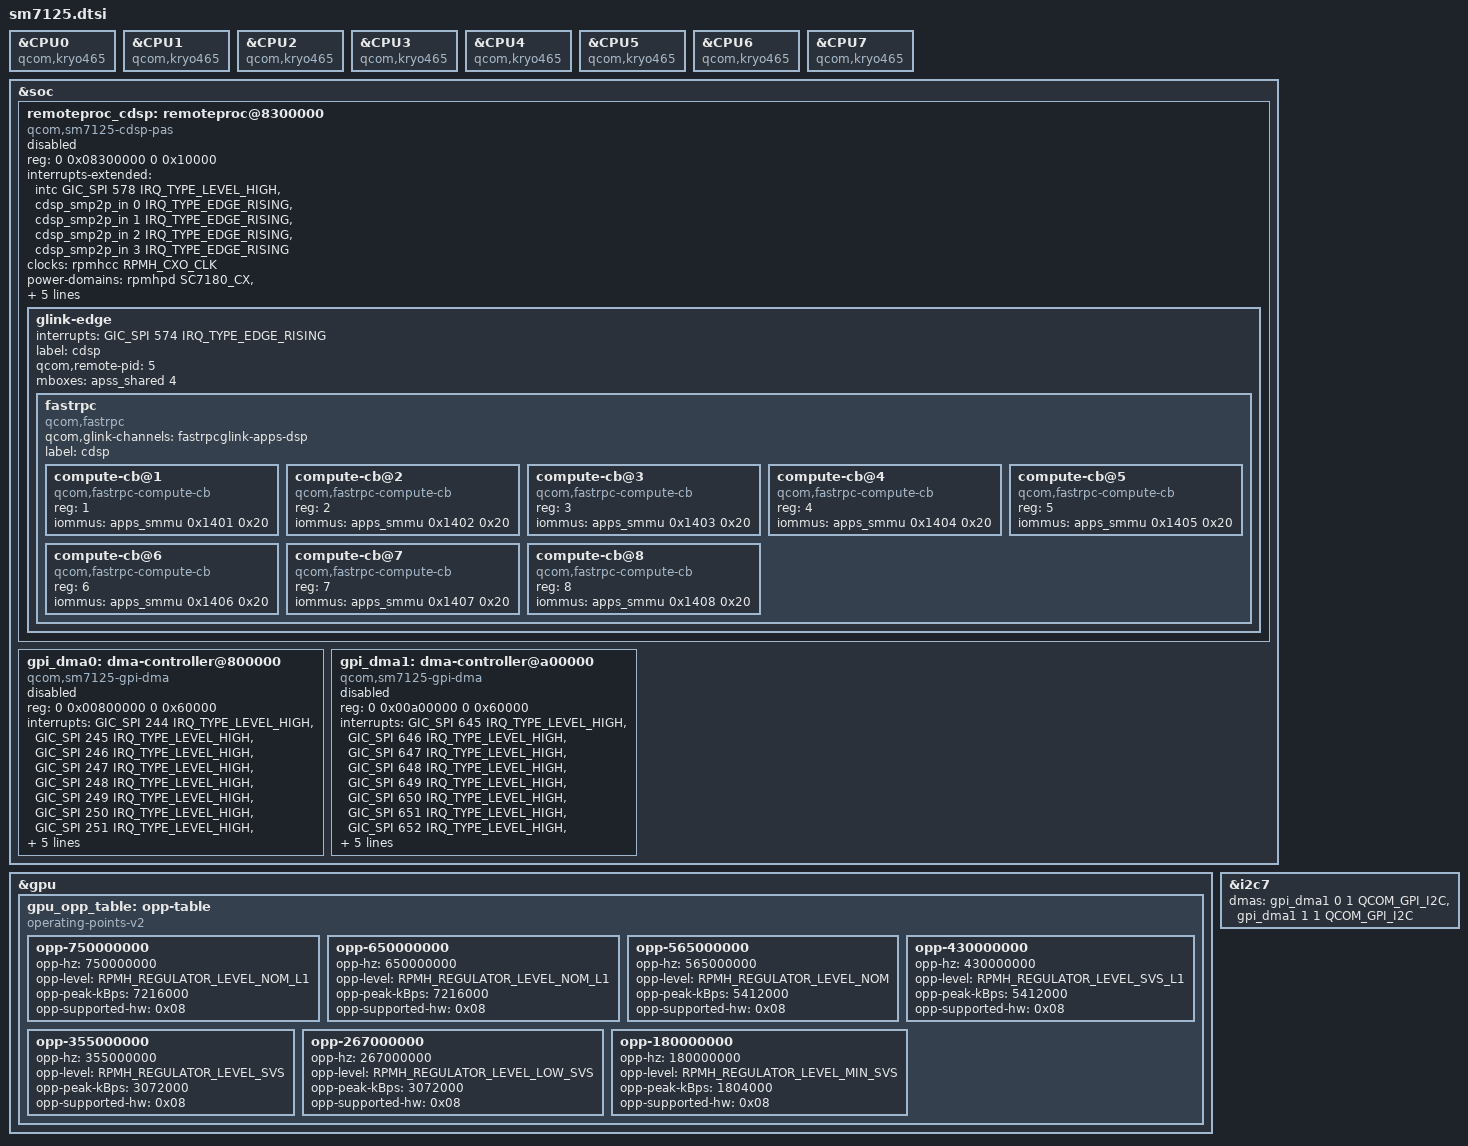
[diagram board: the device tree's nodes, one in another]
// SPDX-License-Identifier: GPL-2.0
/*
 * Copyright (c) 2021, The Linux Foundation. All rights reserved.
 */

#include <dt-bindings/dma/qcom-gpi.h>
#include "sc7180.dtsi"

/* SM7125 uses Kryo 465 instead of Kryo 468 */
&CPU0 { compatible = "qcom,kryo465"; };
&CPU1 { compatible = "qcom,kryo465"; };
&CPU2 { compatible = "qcom,kryo465"; };
&CPU3 { compatible = "qcom,kryo465"; };
&CPU4 { compatible = "qcom,kryo465"; };
&CPU5 { compatible = "qcom,kryo465"; };
&CPU6 { compatible = "qcom,kryo465"; };
&CPU7 { compatible = "qcom,kryo465"; };

&soc {
	remoteproc_cdsp: remoteproc@8300000 {
		compatible = "qcom,sm7125-cdsp-pas", "qcom,sm6350-cdsp-pas";
		reg = <0 0x08300000 0 0x10000>;

		interrupts-extended = <&intc GIC_SPI 578 IRQ_TYPE_LEVEL_HIGH>,
						<&cdsp_smp2p_in 0 IRQ_TYPE_EDGE_RISING>,
						<&cdsp_smp2p_in 1 IRQ_TYPE_EDGE_RISING>,
						<&cdsp_smp2p_in 2 IRQ_TYPE_EDGE_RISING>,
						<&cdsp_smp2p_in 3 IRQ_TYPE_EDGE_RISING>;
		interrupt-names = "wdog", "fatal", "ready",
					"handover", "stop-ack";

		clocks = <&rpmhcc RPMH_CXO_CLK>;
		clock-names = "xo";

		power-domains = <&rpmhpd SC7180_CX>,
				<&rpmhpd SC7180_MX>;
		power-domain-names = "cx", "mx";

		memory-region = <&cdsp_mem>;

		qcom,qmp = <&aoss_qmp>;

		qcom,smem-states = <&cdsp_smp2p_out 0>;
		qcom,smem-state-names = "stop";

		status = "disabled";

		glink-edge {
			interrupts = <GIC_SPI 574 IRQ_TYPE_EDGE_RISING>;
			label = "cdsp";
			qcom,remote-pid = <5>;
			mboxes = <&apss_shared 4>;

			fastrpc {
				compatible = "qcom,fastrpc";
				qcom,glink-channels = "fastrpcglink-apps-dsp";
				label = "cdsp";
				#address-cells = <1>;
				#size-cells = <0>;

				compute-cb@1 {
					compatible = "qcom,fastrpc-compute-cb";
					reg = <1>;
					iommus = <&apps_smmu 0x1401 0x20>;
				};

				compute-cb@2 {
					compatible = "qcom,fastrpc-compute-cb";
					reg = <2>;
					iommus = <&apps_smmu 0x1402 0x20>;
				};

				compute-cb@3 {
					compatible = "qcom,fastrpc-compute-cb";
					reg = <3>;
					iommus = <&apps_smmu 0x1403 0x20>;
				};

				compute-cb@4 {
					compatible = "qcom,fastrpc-compute-cb";
					reg = <4>;
					iommus = <&apps_smmu 0x1404 0x20>;
				};

				compute-cb@5 {
					compatible = "qcom,fastrpc-compute-cb";
					reg = <5>;
					iommus = <&apps_smmu 0x1405 0x20>;
				};

				compute-cb@6 {
					compatible = "qcom,fastrpc-compute-cb";
					reg = <6>;
					iommus = <&apps_smmu 0x1406 0x20>;
				};

				compute-cb@7 {
					compatible = "qcom,fastrpc-compute-cb";
					reg = <7>;
					iommus = <&apps_smmu 0x1407 0x20>;
				};

				compute-cb@8 {
					compatible = "qcom,fastrpc-compute-cb";
					reg = <8>;
					iommus = <&apps_smmu 0x1408 0x20>;
				};

				/* note: secure cb9 in downstream */
			};
		};
	};

	gpi_dma0: dma-controller@800000  {
		compatible = "qcom,sm7125-gpi-dma", "qcom,sm6350-gpi-dma";
		reg = <0 0x00800000 0 0x60000>;
		interrupts = <GIC_SPI 244 IRQ_TYPE_LEVEL_HIGH>,
					<GIC_SPI 245 IRQ_TYPE_LEVEL_HIGH>,
					<GIC_SPI 246 IRQ_TYPE_LEVEL_HIGH>,
					<GIC_SPI 247 IRQ_TYPE_LEVEL_HIGH>,
					<GIC_SPI 248 IRQ_TYPE_LEVEL_HIGH>,
					<GIC_SPI 249 IRQ_TYPE_LEVEL_HIGH>,
					<GIC_SPI 250 IRQ_TYPE_LEVEL_HIGH>,
					<GIC_SPI 251 IRQ_TYPE_LEVEL_HIGH>,
					<GIC_SPI 252 IRQ_TYPE_LEVEL_HIGH>,
					<GIC_SPI 253 IRQ_TYPE_LEVEL_HIGH>;
		dma-channels = <10>;
		dma-channel-mask = <0x1f>;
		iommus = <&apps_smmu 0x56 0x0>;
		#dma-cells = <3>;
		status = "disabled";
	};

	gpi_dma1: dma-controller@a00000 {
		compatible = "qcom,sm7125-gpi-dma", "qcom,sm6350-gpi-dma";
		reg = <0 0x00a00000 0 0x60000>;
		interrupts = <GIC_SPI 645 IRQ_TYPE_LEVEL_HIGH>,
					<GIC_SPI 646 IRQ_TYPE_LEVEL_HIGH>,
					<GIC_SPI 647 IRQ_TYPE_LEVEL_HIGH>,
					<GIC_SPI 648 IRQ_TYPE_LEVEL_HIGH>,
					<GIC_SPI 649 IRQ_TYPE_LEVEL_HIGH>,
					<GIC_SPI 650 IRQ_TYPE_LEVEL_HIGH>,
					<GIC_SPI 651 IRQ_TYPE_LEVEL_HIGH>,
					<GIC_SPI 652 IRQ_TYPE_LEVEL_HIGH>,
					<GIC_SPI 653 IRQ_TYPE_LEVEL_HIGH>,
					<GIC_SPI 654 IRQ_TYPE_LEVEL_HIGH>;
		dma-channels = <10>;
		dma-channel-mask = <0x3f>;
		iommus = <&apps_smmu 0x4d6 0x0>;
		#dma-cells = <3>;
		status = "disabled";
	};
};

/delete-node/ &gpu_opp_table;
&gpu {
	gpu_opp_table: opp-table {
		compatible = "operating-points-v2";

		opp-750000000 {
			opp-hz = /bits/ 64 <750000000>;
			opp-level = <RPMH_REGULATOR_LEVEL_NOM_L1>;
			opp-peak-kBps = <7216000>;
			opp-supported-hw = <0x08>;
		};

		opp-650000000 {
			opp-hz = /bits/ 64 <650000000>;
			opp-level = <RPMH_REGULATOR_LEVEL_NOM_L1>;
			opp-peak-kBps = <7216000>;
			opp-supported-hw = <0x08>;
		};

		opp-565000000 {
			opp-hz = /bits/ 64 <565000000>;
			opp-level = <RPMH_REGULATOR_LEVEL_NOM>;
			opp-peak-kBps = <5412000>;
			opp-supported-hw = <0x08>;
		};

		opp-430000000 {
			opp-hz = /bits/ 64 <430000000>;
			opp-level = <RPMH_REGULATOR_LEVEL_SVS_L1>;
			opp-peak-kBps = <5412000>;
			opp-supported-hw = <0x08>;
		};

		opp-355000000 {
			opp-hz = /bits/ 64 <355000000>;
			opp-level = <RPMH_REGULATOR_LEVEL_SVS>;
			opp-peak-kBps = <3072000>;
			opp-supported-hw = <0x08>;
		};

		opp-267000000 {
			opp-hz = /bits/ 64 <267000000>;
			opp-level = <RPMH_REGULATOR_LEVEL_LOW_SVS>;
			opp-peak-kBps = <3072000>;
			opp-supported-hw = <0x08>;
		};

		opp-180000000 {
			opp-hz = /bits/ 64 <180000000>;
			opp-level = <RPMH_REGULATOR_LEVEL_MIN_SVS>;
			opp-peak-kBps = <1804000>;
			opp-supported-hw = <0x08>;
		};
	};
};

&i2c7 {
	dmas = <&gpi_dma1 0 1 QCOM_GPI_I2C>,
			<&gpi_dma1 1 1 QCOM_GPI_I2C>;
	dma-names = "tx", "rx";
};
